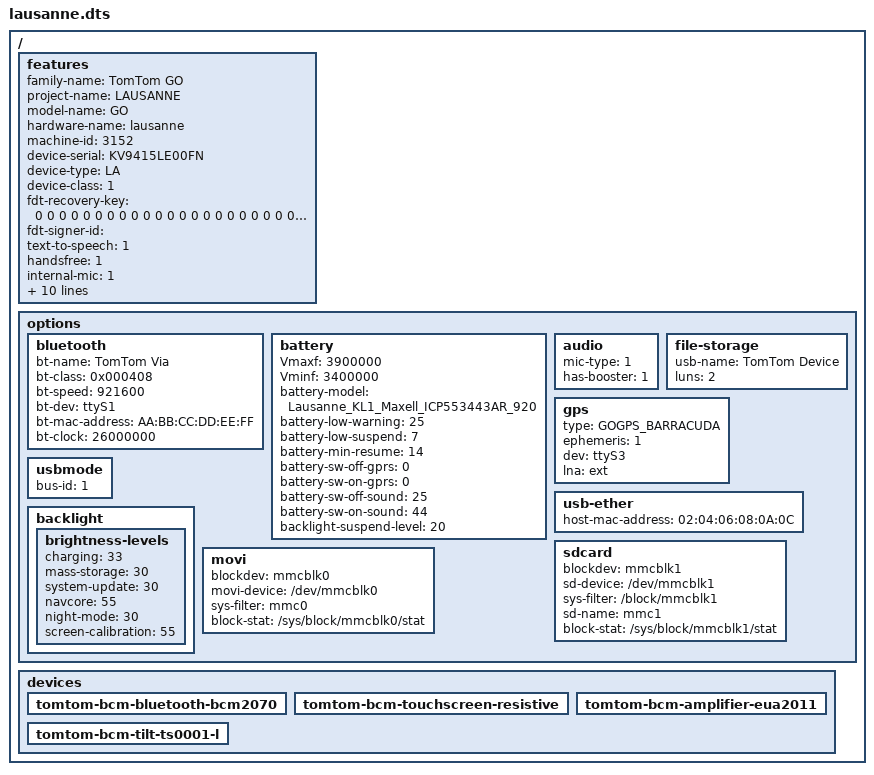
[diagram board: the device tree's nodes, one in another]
/dts-v1/;

/ {
	features {
		family-name			= "TomTom GO";
		project-name			= "LAUSANNE";
		model-name			= "GO";
		hardware-name			= "lausanne";
		machine-id			= <3152>;
		device-serial			= "KV9415LE00FN";
		device-type			= "LA";
		device-class			= <1>;
		fdt-recovery-key		= <
			0 0 0 0 0 0 0 0 0 0 0 0 0 0 0 0 0 0 0 0 0 0 0 0 0 0 0 0 0 0 0 0
			0 0 0 0 0 0 0 0 0 0 0 0 0 0 0 0 0 0 0 0 0 0 0 0 0 0 0 0 0 0 0 0
			0 0 0 0 0 0 0 0 0 0 0 0 0 0 0 0 0 0 0 0 0 0 0 0 0 0 0 0 0 0 0 0
			0 0 0 0 0 0 0 0 0 0 0 0 0 0 0 0 0 0 0 0 0 0 0 0 0 0 0 0 0 0 0 0
		>;
		fdt-signer-id			= "";
		text-to-speech			= <1>;
		handsfree			= <1>;
		internal-mic			= <1>;
		voice-recording			= <1>;
		connect-ext-mic			= <0>;
		sdcard				= <1>;
		uart-id				= <2>;
		has-gprs			= <0>;
		has-tilt-sensor			= <1>;
		has-bluetooth			= <1>;
		bluetooth			= "BCM2070";
		amplifier			= "EUA2011";
		tft 				= "LMS500";
	};

	options {
		bluetooth {
			bt-name 			= "TomTom Via";
			bt-class 			= <0x000408>;
			bt-speed 			= <921600>;
			bt-dev 				= "ttyS1";
			bt-mac-address 			= "AA:BB:CC:DD:EE:FF";
			bt-clock 			= <26000000>;

		};

		battery {
			Vmaxf = <3900000>;
			Vminf = <3400000>;
			/* The battery model is composed as: packvendor_cellvendor_batterytype_batterycapacity */
			battery-model			= "Lausanne_KL1_Maxell_ICP553443AR_920";
			battery-low-warning		= <25>;
			battery-low-suspend		= <7>;
			battery-min-resume		= <14>;
			battery-sw-off-gprs		= <0>;
			battery-sw-on-gprs		= <0>;
			battery-sw-off-sound		= <25>;
			battery-sw-on-sound		= <44>;
			backlight-suspend-level		= <20>;
		};

		audio {
			mic-type			= <1>;	/* 1 = rubber mic, 2 = SMT mic */
			has-booster			= <1>;
		};

		file-storage {
			usb-name			= "TomTom Device";
			luns				= <2>;
		};

		gps {
			type 				= "GOGPS_BARRACUDA";
			ephemeris			= <1>;			
			dev				= "ttyS3";
			lna				= "ext";
		};

		usb-ether 
		{
			host-mac-address		= "02:04:06:08:0A:0C";
		};

		usbmode 
		{
			/* usbmode related , the id of the usbmode driver needs change */
			bus-id				= <1>; 
		};

		backlight 
		{
			brightness-levels 
			{
				charging		= <33>;
				mass-storage		= <30>;
				system-update		= <30>;
				navcore			= <55>;
				night-mode		= <30>;
				screen-calibration	= <55>;
			};
		};

		sdcard 
		{
			blockdev 	= "mmcblk1";
			sd-device 	= "/dev/mmcblk1";
			sys-filter 	= "/block/mmcblk1";
			sd-name 	= "mmc1";
			block-stat 	= "/sys/block/mmcblk1/stat";
		};

		movi { 
			blockdev 	= "mmcblk0";
			movi-device 	= "/dev/mmcblk0";
			sys-filter 	= "mmc0";
			block-stat 	= "/sys/block/mmcblk0/stat";
		};

	};

	/* list of tomtom methods that need implementing: adding items as devices
	will cause tt_setup to register the services */
	devices 
	{
		tomtom-bcm-bluetooth-bcm2070 {};
		tomtom-bcm-touchscreen-resistive {};
		tomtom-bcm-amplifier-eua2011 {};
		tomtom-bcm-tilt-ts0001-l {};
	};
};
